# GD32F5HC register map
File version: 1.0
CPU: CM33 r0p4, little endian, MPU, FPU, 4 interrupt priority bits
Registers are 32-bit, read-write, reset 0x0 unless marked. A register's access mark holds for its fields unless they carry their own. Offsets are from the block's base; [hi:lo] are bit positions; {n}, {i} and the like mark numbered series.

## TRNG — Ture random number generator
Base 0x4C060800
Same registers: SEC_TRNG 0x5C060800
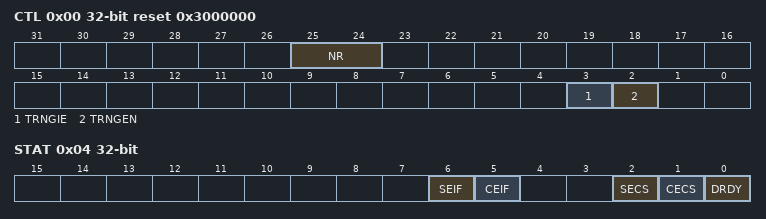
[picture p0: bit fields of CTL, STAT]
0x00 CTL reset 0x3000000 — Control register
  [25:24] NR — TRNG power mode
  [3] TRNGIE — TRNG interrupt bit
  [2] TRNGEN — TRNG enable bit
0x04 STAT access per field — Status register
  [6] SEIF rw — Seed error interrupt flag
  [5] CEIF rw — Clock error interrupt flag
  [2] SECS ro — Seed error current status
  [1] CECS ro — Clock error current status
  [0] DRDY ro — Random data ready status bit
0x08 DATA ro
  [31:0] TRNDATA — 32-bit random data

## TZBMPC0 — Memory protection controller - block based
Base 0x400A0800
Same registers: SEC_TZBMPC0 0x500A0800
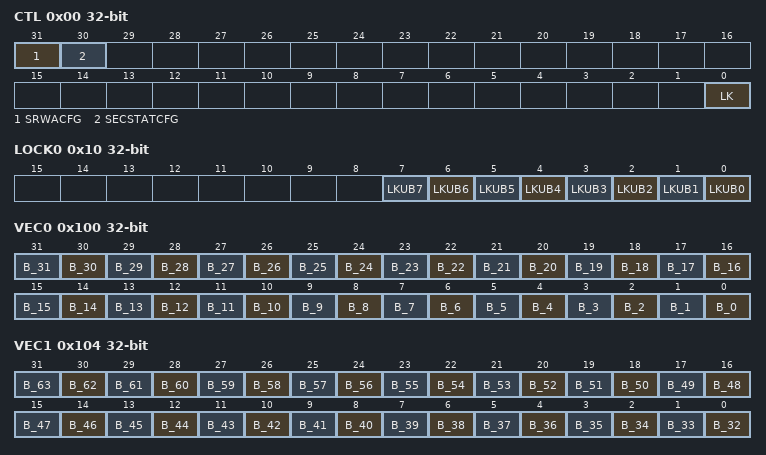
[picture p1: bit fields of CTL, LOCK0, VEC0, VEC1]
0x00 CTL — TZBMPC0 control register
  [31] SRWACFG — secure read/write illegal access disable
  [30] SECSTATCFG — default security state
  [0] LK — TZSPC items lock configuration bit
0x10 LOCK0 — TZBMPC0 lock register 0
  [n] LKUB{n} (n=0..7) — lock/unlock status of secure access mode for the super-blocks {n}
0x100 VEC0 — TZBMPC0 vector register 0
  [n] B_{n} (n=0..31) — blocks {n}
0x104 VEC1 — TZBMPC0 vector register 1
  [n-32] B_{n} (n=32..63) — blocks {n}
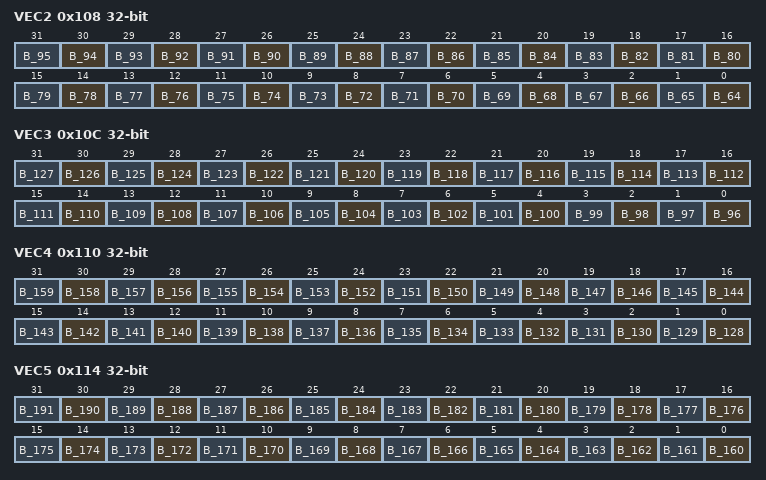
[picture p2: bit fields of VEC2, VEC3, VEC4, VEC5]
0x108 VEC2 — TZBMPC0 vector register 2
  [n-64] B_{n} (n=64..95) — blocks {n}
0x10C VEC3 — TZBMPC0 vector register 3
  [n-96] B_{n} (n=96..127) — blocks {n}
0x110 VEC4 — TZBMPC0 vector register 4
  [n-128] B_{n} (n=128..159) — blocks {n}
0x114 VEC5 — TZBMPC0 vector register 5
  [n-160] B_{n} (n=160..191) — blocks {n}
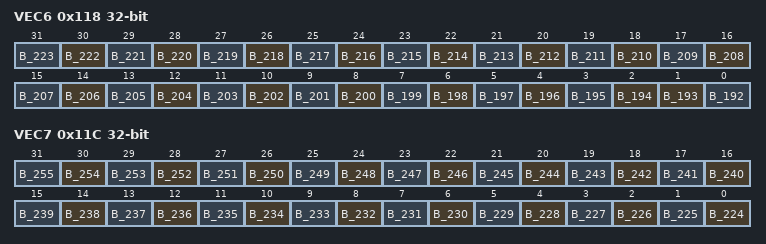
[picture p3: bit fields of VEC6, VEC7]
0x118 VEC6 — TZBMPC0 vector register 6
  [n-192] B_{n} (n=194..223) — blocks {n}
  [1] B_193 — blocks 93
  [0] B_192 — blocks 192
0x11C VEC7 — TZBMPC0 vector register 7
  [n-224] B_{n} (n=224..255) — blocks {n}

## TZBMPC1 — Memory protection controller - block based
Base 0x400A0C00
Same registers: SEC_TZBMPC1 0x500A0C00
Registers as TZBMPC0 (with TZBMPC0 read as TZBMPC1); these are added or differ:
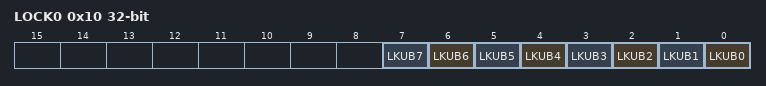
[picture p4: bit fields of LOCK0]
0x10 LOCK0 — TZBMPC1 lock register0
  [n] LKUB{n} (n=0..7) — lock/unlock status of secure access mode for the super-blocks {n}

## TZBMPC2 — Memory protection controller - block based
Base 0x400B0000
Same registers: SEC_TZBMPC2 0x500B0000
Registers as TZBMPC0 (with TZBMPC0 read as TZBMPC2); these are added or differ:
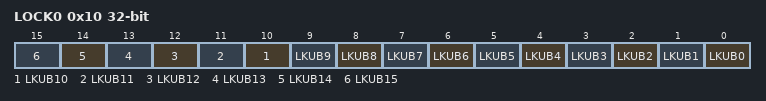
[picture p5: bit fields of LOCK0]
0x10 LOCK0 — TZBMPC2 lock register 0
  [n] LKUB{n} (n=0..15) — lock/unlock status of secure access mode for the super-blocks {n}

## TZBMPC3 — Memory protection controller - block based
Base 0x400B0400
Same registers: SEC_TZBMPC3 0x500B0400
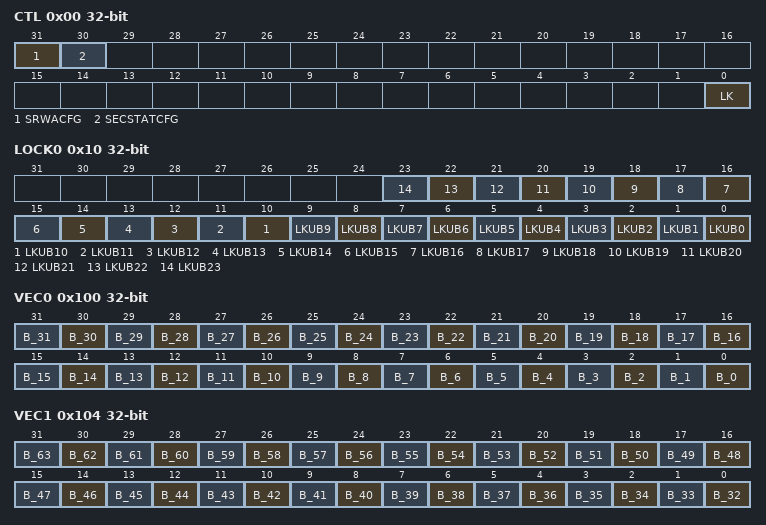
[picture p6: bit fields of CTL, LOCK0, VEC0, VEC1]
0x00 CTL — TZBMPC2 control register
  [31] SRWACFG — secure read/write illegal access disable
  [30] SECSTATCFG — default security state
  [0] LK — TZSPC items lock configuration bit
0x10 LOCK0 — TZBMPC1 lock register0
  [n] LKUB{n} (n=0..23) — lock/unlock status of secure access mode for the super-blocks {n}
0x100 VEC0 — TZBMPC3 vector register 0
  [n] B_{n} (n=0..31) — blocks {n}
0x104 VEC1 — TZBMPC3 vector register 1
  [n-32] B_{n} (n=32..63) — blocks {n}
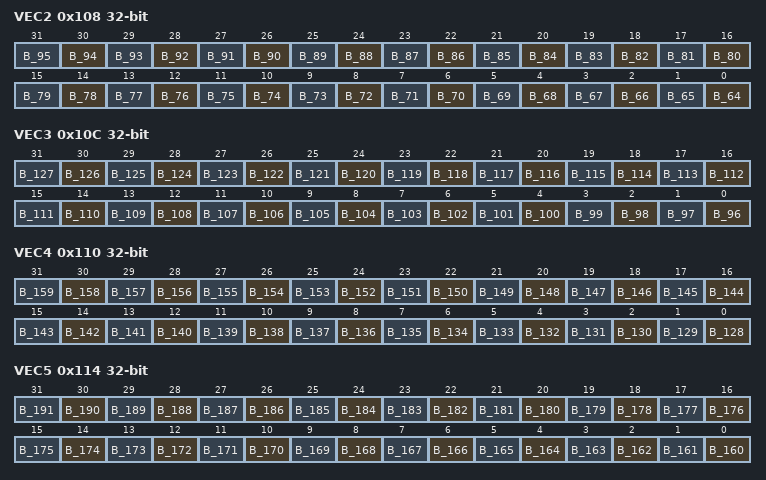
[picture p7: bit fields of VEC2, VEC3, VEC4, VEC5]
0x108 VEC2 — TZBMPC3 vector register 2
  [n-64] B_{n} (n=64..95) — blocks {n}
0x10C VEC3 — TZBMPC3 vector register 3
  [n-96] B_{n} (n=96..127) — blocks {n}
0x110 VEC4 — TZBMPC3 vector register 4
  [n-128] B_{n} (n=128..159) — blocks {n}
0x114 VEC5 — TZBMPC3 vector register 5
  [n-160] B_{n} (n=160..191) — blocks {n}
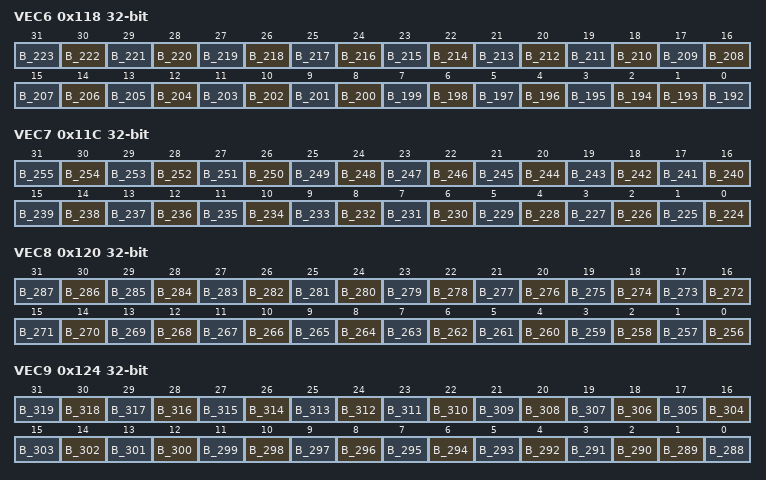
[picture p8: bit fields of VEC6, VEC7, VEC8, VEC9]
0x118 VEC6 — TZBMPC3 vector register 6
  [n-192] B_{n} (n=194..223) — blocks {n}
  [1] B_193 — blocks 93
  [0] B_192 — blocks 192
0x11C VEC7 — TZBMPC3 vector register 7
  [n-224] B_{n} (n=224..255) — blocks {n}
0x120 VEC8 — TZBMPC3 vector register 8
  [n-256] B_{n} (n=256..287) — blocks {n}
0x124 VEC9 — TZBMPC3 vector register 9
  [n-288] B_{n} (n=290..319) — blocks{n}
  [1] B_289 — blocks 289
  [0] B_288 — blocks 288
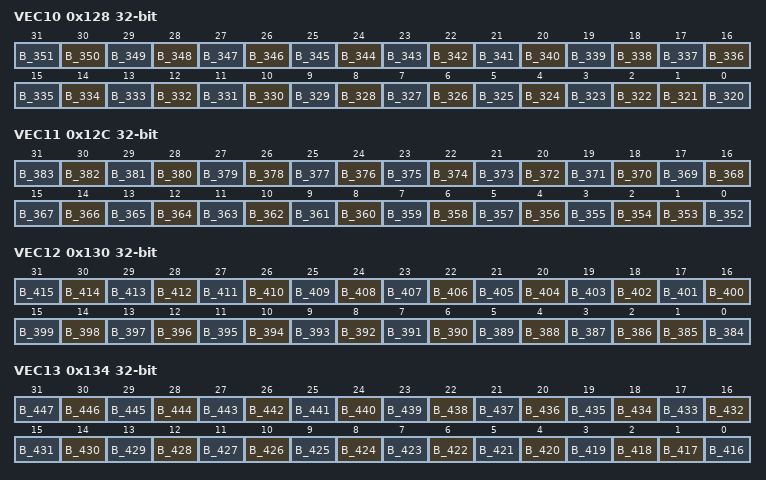
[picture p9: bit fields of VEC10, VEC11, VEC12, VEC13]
0x128 VEC10 — TZBMPC3 vector register 10
  [n-320] B_{n} (n=322..351) — blocks{n}
  [1] B_321 — blocks 321
  [0] B_320 — blocks 320
0x12C VEC11 — TZBMPC3 vector register 11
  [n-352] B_{n} (n=354..383) — blocks{n}
  [1] B_353 — blocks 353
  [0] B_352 — blocks 352
0x130 VEC12 — TZBMPC3 vector register 12
  [n-384] B_{n} (n=386..415) — blocks{n}
  [1] B_385 — blocks 385
  [0] B_384 — blocks 384
0x134 VEC13 — TZBMPC3 vector register 13
  [n-416] B_{n} (n=418..447) — blocks{n}
  [1] B_417 — blocks 417
  [0] B_416 — blocks 416
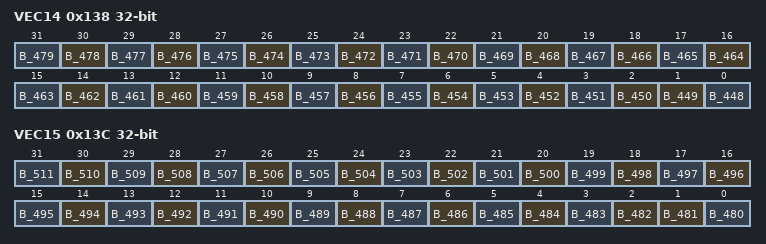
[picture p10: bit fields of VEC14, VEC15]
0x138 VEC14 — TZBMPC3 vector register 14
  [n-448] B_{n} (n=450..479) — blocks{n}
  [1] B_449 — blocks 449
  [0] B_448 — blocks 448
0x13C VEC15 — TZBMPC3 vector register 15
  [n-480] B_{n} (n=482..511) — blocks{n}
  [1] B_481 — blocks 481
  [0] B_480 — blocks 480
